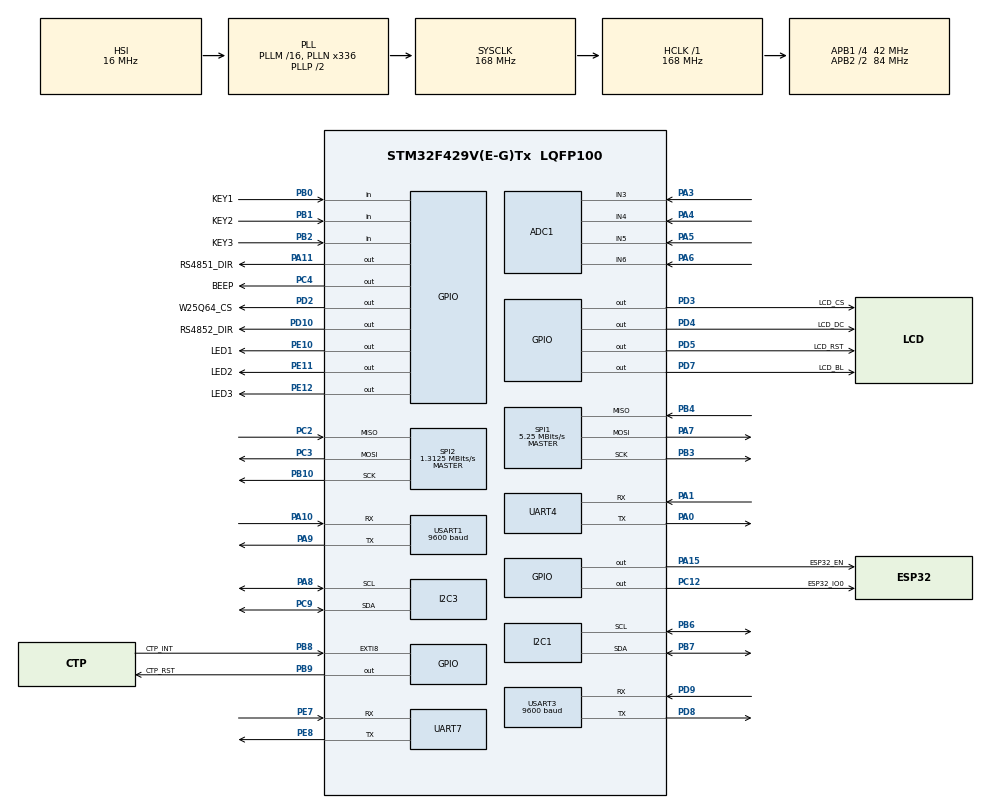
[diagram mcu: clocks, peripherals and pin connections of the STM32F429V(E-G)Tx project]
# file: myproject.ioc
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ADC1.Channel-1\#ChannelRegularConversion=ADC_CHANNEL_3
ADC1.Channel-2\#ChannelInjectedConversion=ADC_CHANNEL_3
ADC1.Channel-3\#ChannelInjectedConversion=ADC_CHANNEL_4
ADC1.Channel-4\#ChannelInjectedConversion=ADC_CHANNEL_5
ADC1.Channel-5\#ChannelInjectedConversion=ADC_CHANNEL_6
ADC1.ContinuousConvMode=ENABLE
ADC1.DMAContinuousRequests=ENABLE
ADC1.InjNumberOfConversion=4
ADC1.InjectedOffset-2\#ChannelInjectedConversion=0
ADC1.InjectedOffset-3\#ChannelInjectedConversion=0
ADC1.InjectedOffset-4\#ChannelInjectedConversion=0
ADC1.InjectedOffset-5\#ChannelInjectedConversion=0
ADC1.InjectedRank-2\#ChannelInjectedConversion=1
ADC1.InjectedRank-3\#ChannelInjectedConversion=2
ADC1.InjectedRank-4\#ChannelInjectedConversion=3
ADC1.InjectedRank-5\#ChannelInjectedConversion=4
ADC1.NbrOfConversionFlag=1
ADC1.Rank-1\#ChannelRegularConversion=1
ADC1.SamplingTime-1\#ChannelRegularConversion=ADC_SAMPLETIME_3CYCLES
ADC1.SamplingTime-2\#ChannelInjectedConversion=ADC_SAMPLETIME_144CYCLES
ADC1.SamplingTime-3\#ChannelInjectedConversion=ADC_SAMPLETIME_144CYCLES
ADC1.SamplingTime-4\#ChannelInjectedConversion=ADC_SAMPLETIME_144CYCLES
ADC1.SamplingTime-5\#ChannelInjectedConversion=ADC_SAMPLETIME_144CYCLES
ADC1.ScanConvMode=ENABLE
ADC1.master=1
Dma.ADC1.0.Direction=DMA_PERIPH_TO_MEMORY
Dma.ADC1.0.FIFOMode=DMA_FIFOMODE_DISABLE
Dma.ADC1.0.Instance=DMA2_Stream0
Dma.ADC1.0.MemDataAlignment=DMA_MDATAALIGN_HALFWORD
Dma.ADC1.0.MemInc=DMA_MINC_ENABLE
Dma.ADC1.0.Mode=DMA_CIRCULAR
Dma.ADC1.0.PeriphDataAlignment=DMA_PDATAALIGN_HALFWORD
Dma.ADC1.0.PeriphInc=DMA_PINC_DISABLE
Dma.ADC1.0.Priority=DMA_PRIORITY_LOW
Dma.Request0=ADC1
Dma.Request1=UART7_RX
Dma.Request2=SPI1_TX
Dma.Request3=USART3_RX
Dma.SPI1_TX.2.Direction=DMA_MEMORY_TO_PERIPH
Dma.SPI1_TX.2.FIFOMode=DMA_FIFOMODE_DISABLE
Dma.SPI1_TX.2.Instance=DMA2_Stream3
Dma.SPI1_TX.2.MemDataAlignment=DMA_MDATAALIGN_BYTE
Dma.SPI1_TX.2.MemInc=DMA_MINC_ENABLE
Dma.SPI1_TX.2.Mode=DMA_CIRCULAR
Dma.SPI1_TX.2.PeriphDataAlignment=DMA_PDATAALIGN_BYTE
Dma.SPI1_TX.2.PeriphInc=DMA_PINC_DISABLE
Dma.SPI1_TX.2.Priority=DMA_PRIORITY_LOW
Dma.UART7_RX.1.Direction=DMA_PERIPH_TO_MEMORY
Dma.UART7_RX.1.FIFOMode=DMA_FIFOMODE_DISABLE
Dma.UART7_RX.1.Instance=DMA1_Stream3
Dma.UART7_RX.1.MemDataAlignment=DMA_MDATAALIGN_BYTE
Dma.UART7_RX.1.MemInc=DMA_MINC_ENABLE
Dma.UART7_RX.1.Mode=DMA_CIRCULAR
Dma.UART7_RX.1.PeriphDataAlignment=DMA_PDATAALIGN_BYTE
Dma.UART7_RX.1.PeriphInc=DMA_PINC_DISABLE
Dma.UART7_RX.1.Priority=DMA_PRIORITY_LOW
Dma.USART3_RX.3.Direction=DMA_PERIPH_TO_MEMORY
Dma.USART3_RX.3.FIFOMode=DMA_FIFOMODE_DISABLE
Dma.USART3_RX.3.Instance=DMA1_Stream1
Dma.USART3_RX.3.MemDataAlignment=DMA_MDATAALIGN_BYTE
Dma.USART3_RX.3.MemInc=DMA_MINC_ENABLE
Dma.USART3_RX.3.Mode=DMA_CIRCULAR
Dma.USART3_RX.3.PeriphDataAlignment=DMA_PDATAALIGN_BYTE
Dma.USART3_RX.3.PeriphInc=DMA_PINC_DISABLE
Dma.USART3_RX.3.Priority=DMA_PRIORITY_LOW
FREERTOS.Tasks01=defaultTask,24,128,StartDefaultTask,Default,NULL,Dynamic,NULL,NULL
I2C1.I2C_Mode=I2C_Fast
IWDG.Prescaler=IWDG_PRESCALER_32
Mcu.Family=STM32F4
Mcu.Name=STM32F429V(E-G)Tx
Mcu.Package=LQFP100
NVIC.ADC_IRQn=true\:5\:0\:false\:false\:true\:true\:true\:true\:true
NVIC.DMA1_Stream1_IRQn=true\:5\:0\:false\:false\:true\:true\:false\:true\:true
NVIC.DMA1_Stream3_IRQn=true\:5\:0\:false\:false\:true\:true\:false\:true\:true
NVIC.DMA2_Stream0_IRQn=true\:5\:0\:false\:false\:true\:true\:false\:true\:true
NVIC.DMA2_Stream3_IRQn=true\:5\:0\:false\:false\:true\:true\:false\:true\:true
NVIC.EXTI9_5_IRQn=true\:5\:0\:false\:false\:true\:true\:true\:true\:true
NVIC.I2C1_ER_IRQn=true\:5\:0\:false\:false\:true\:true\:true\:true\:true
NVIC.I2C1_EV_IRQn=true\:5\:0\:false\:false\:true\:true\:true\:true\:true
NVIC.I2C3_ER_IRQn=true\:5\:0\:false\:false\:true\:true\:true\:true\:true
NVIC.I2C3_EV_IRQn=true\:5\:0\:false\:false\:true\:true\:true\:true\:true
NVIC.PriorityGroup=NVIC_PRIORITYGROUP_4
NVIC.SPI1_IRQn=true\:5\:0\:false\:false\:true\:true\:true\:true\:true
NVIC.SPI2_IRQn=true\:5\:0\:false\:false\:true\:true\:true\:true\:true
NVIC.TIM6_DAC_IRQn=true\:15\:0\:false\:false\:true\:false\:false\:true\:true
NVIC.TimeBase=TIM6_DAC_IRQn
NVIC.TimeBaseIP=TIM6
NVIC.UART4_IRQn=true\:5\:0\:false\:false\:true\:true\:true\:true\:true
NVIC.UART7_IRQn=true\:5\:0\:false\:false\:true\:true\:true\:true\:true
NVIC.USART1_IRQn=true\:5\:0\:false\:false\:true\:true\:true\:true\:true
NVIC.USART3_IRQn=true\:5\:0\:false\:false\:true\:true\:true\:true\:true
PA0/WKUP.Mode=Asynchronous
PA0/WKUP.Signal=UART4_TX
PA1.Mode=Asynchronous
PA1.Signal=UART4_RX
PA10.Mode=Asynchronous
PA10.Signal=USART1_RX
PA11.GPIO_Label=RS4851_DIR
PA11.GPIO_Speed=GPIO_SPEED_FREQ_HIGH
PA11.Signal=GPIO_Output
PA13.Mode=Serial_Wire
PA13.Signal=SYS_JTMS-SWDIO
PA14.Mode=Serial_Wire
PA14.Signal=SYS_JTCK-SWCLK
PA15.GPIO_Label=ESP32_EN
PA15.GPIO_Speed=GPIO_SPEED_FREQ_MEDIUM
PA15.PinState=GPIO_PIN_SET
PA15.Signal=GPIO_Output
PA3.Signal=ADCx_IN3
PA4.Signal=ADCx_IN4
PA5.Signal=ADCx_IN5
PA6.Signal=ADCx_IN6
PA7.Mode=Full_Duplex_Master
PA7.Signal=SPI1_MOSI
PA8.Mode=I2C
PA8.Signal=I2C3_SCL
PA9.Mode=Asynchronous
PA9.Signal=USART1_TX
PB0.GPIO_Label=KEY1
PB0.GPIO_PuPd=GPIO_PULLUP
PB0.Signal=GPIO_Input
PB1.GPIO_Label=KEY2
PB1.GPIO_PuPd=GPIO_PULLUP
PB1.Signal=GPIO_Input
PB10.Mode=Full_Duplex_Master
PB10.Signal=SPI2_SCK
PB2/BOOT1.GPIO_Label=KEY3
PB2/BOOT1.GPIO_PuPd=GPIO_PULLUP
PB2/BOOT1.Signal=GPIO_Input
PB3.Mode=Full_Duplex_Master
PB3.Signal=SPI1_SCK
PB4.Mode=Full_Duplex_Master
PB4.Signal=SPI1_MISO
PB6.Mode=I2C
PB6.Signal=I2C1_SCL
PB7.Mode=I2C
PB7.Signal=I2C1_SDA
PB8.GPIO_Label=CTP_INT
PB8.GPIO_PuPd=GPIO_PULLUP
PB8.Signal=GPXTI8
PB9.GPIO_Label=CTP_RST
PB9.GPIO_Speed=GPIO_SPEED_FREQ_MEDIUM
PB9.PinState=GPIO_PIN_SET
PB9.Signal=GPIO_Output
PC12.GPIO_Label=ESP32_IO0
PC12.GPIO_Speed=GPIO_SPEED_FREQ_HIGH
PC12.PinState=GPIO_PIN_SET
PC12.Signal=GPIO_Output
PC14/OSC32_IN.Mode=LSE-External-Oscillator
PC14/OSC32_IN.Signal=RCC_OSC32_IN
PC15/OSC32_OUT.Mode=LSE-External-Oscillator
PC15/OSC32_OUT.Signal=RCC_OSC32_OUT
PC2.Mode=Full_Duplex_Master
PC2.Signal=SPI2_MISO
PC3.Mode=Full_Duplex_Master
PC3.Signal=SPI2_MOSI
PC4.GPIO_Label=BEEP
PC4.Signal=GPIO_Output
PC9.Mode=I2C
PC9.Signal=I2C3_SDA
PD10.GPIO_Label=RS4852_DIR
PD10.GPIO_Speed=GPIO_SPEED_FREQ_HIGH
PD10.Signal=GPIO_Output
PD2.GPIO_Label=W25Q64_CS
PD2.GPIO_Speed=GPIO_SPEED_FREQ_HIGH
PD2.PinState=GPIO_PIN_SET
PD2.Signal=GPIO_Output
PD3.GPIO_Label=LCD_CS
PD3.GPIO_Speed=GPIO_SPEED_FREQ_VERY_HIGH
PD3.PinState=GPIO_PIN_SET
PD3.Signal=GPIO_Output
PD4.GPIO_Label=LCD_DC
PD4.Signal=GPIO_Output
PD5.GPIO_Label=LCD_RST
PD5.GPIO_Speed=GPIO_SPEED_FREQ_HIGH
PD5.PinState=GPIO_PIN_SET
PD5.Signal=GPIO_Output
PD7.GPIO_Label=LCD_BL
PD7.PinState=GPIO_PIN_SET
PD7.Signal=GPIO_Output
PD8.Mode=Asynchronous
PD8.Signal=USART3_TX
PD9.Mode=Asynchronous
PD9.Signal=USART3_RX
PE10.GPIO_Label=LED1
PE10.Signal=GPIO_Output
PE11.GPIO_Label=LED2
PE11.Signal=GPIO_Output
PE12.GPIO_Label=LED3
PE12.Signal=GPIO_Output
PE7.Mode=Asynchronous
PE7.Signal=UART7_RX
PE8.Mode=Asynchronous
PE8.Signal=UART7_TX
PH0/OSC_IN.Mode=HSE-External-Oscillator
PH0/OSC_IN.Signal=RCC_OSC_IN
PH1/OSC_OUT.Mode=HSE-External-Oscillator
PH1/OSC_OUT.Signal=RCC_OSC_OUT
ProjectManager.HeapSize=0x4000
ProjectManager.StackSize=0x2000
ProjectManager.TargetToolchain=CMake
RCC.48MHZClocksFreq_Value=84000000
RCC.AHBFreq_Value=168000000
RCC.APB1CLKDivider=RCC_HCLK_DIV4
RCC.APB1Freq_Value=42000000
RCC.APB1TimFreq_Value=84000000
RCC.APB2CLKDivider=RCC_HCLK_DIV2
RCC.APB2Freq_Value=84000000
RCC.APB2TimFreq_Value=168000000
RCC.CortexFreq_Value=168000000
RCC.HCLKFreq_Value=168000000
RCC.HSE_VALUE=25000000
RCC.HSI_VALUE=16000000
RCC.PLLN=336
RCC.SYSCLKFreq_VALUE=168000000
RCC.SYSCLKSource=RCC_SYSCLKSOURCE_PLLCLK
RCC.VCOOutputFreq_Value=336000000
SH.ADCx_IN3.0=ADC1_IN3,IN3
SH.ADCx_IN4.0=ADC1_IN4,IN4
SH.ADCx_IN5.0=ADC1_IN5,IN5
SH.ADCx_IN6.0=ADC1_IN6,IN6
SPI1.BaudRatePrescaler=SPI_BAUDRATEPRESCALER_16
SPI1.CalculateBaudRate=5.25 MBits/s
SPI1.Direction=SPI_DIRECTION_2LINES
SPI1.Mode=SPI_MODE_MASTER
SPI1.VirtualType=VM_MASTER
SPI2.BaudRatePrescaler=SPI_BAUDRATEPRESCALER_32
SPI2.CalculateBaudRate=1.3125 MBits/s
SPI2.Direction=SPI_DIRECTION_2LINES
SPI2.Mode=SPI_MODE_MASTER
SPI2.VirtualType=VM_MASTER
UART4.VirtualMode=Asynchronous
UART7.VirtualMode=Asynchronous
USART1.BaudRate=9600
USART1.VirtualMode=VM_ASYNC
USART3.BaudRate=9600
USART3.VirtualMode=VM_ASYNC
VP_FREERTOS_VS_CMSIS_V2.Mode=CMSIS_V2
VP_IWDG_VS_IWDG.Mode=IWDG_Activate
VP_SYS_VS_tim6.Mode=TIM6
board=custom

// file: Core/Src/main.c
/* USER CODE BEGIN Header */
/**
  ******************************************************************************
  * @file           : main.c
  * @brief          : Main program body
  ******************************************************************************
  * @attention
  *
  * Copyright (c) 2026 STMicroelectronics.
  * All rights reserved.
  *
  * This software is licensed under terms that can be found in the LICENSE file
  * in the root directory of this software component.
  * If no LICENSE file comes with this software, it is provided AS-IS.
  *
  ******************************************************************************
  */
/* USER CODE END Header */
#include "main.h"
#include "cmsis_os.h"
#include "adc.h"
#include "dma.h"
#include "i2c.h"
#include "iwdg.h"
#include "spi.h"
#include "usart.h"
#include "gpio.h"

/* USER CODE BEGIN Includes */
#include "app_main.h"
/* USER CODE END Includes */

void SystemClock_Config(void);
void MX_FREERTOS_Init(void);

int main(void)
{

  /* MCU Configuration--------------------------------------------------------*/

  /* Reset of all peripherals, Initializes the Flash interface and the Systick. */
  HAL_Init();

  /* Configure the system clock */
  SystemClock_Config();

  /* Initialize all configured peripherals */
  MX_GPIO_Init();
  MX_DMA_Init();
  MX_USART1_UART_Init();
  MX_ADC1_Init();
  MX_I2C1_Init();
  MX_I2C3_Init();
  MX_SPI1_Init();
  MX_SPI2_Init();
  MX_UART4_Init();
  MX_UART7_Init();
  MX_USART3_UART_Init();
  MX_IWDG_Init();
  /* USER CODE BEGIN 2 */

  App_MainInit();
  /* USER CODE END 2 */

  /* Init scheduler */
  osKernelInitialize();

  /* Call init function for freertos objects (in cmsis_os2.c) */
  MX_FREERTOS_Init();

  /* Start scheduler */
  osKernelStart();

  /* We should never get here as control is now taken by the scheduler */

  /* Infinite loop */
  while (1)
  {

  }
}

void SystemClock_Config(void)
{
  RCC_OscInitTypeDef RCC_OscInitStruct = {0};
  RCC_ClkInitTypeDef RCC_ClkInitStruct = {0};

  /** Configure the main internal regulator output voltage
  */
  __HAL_RCC_PWR_CLK_ENABLE();
  __HAL_PWR_VOLTAGESCALING_CONFIG(PWR_REGULATOR_VOLTAGE_SCALE1);

  /** Initializes the RCC Oscillators according to the specified parameters
  * in the RCC_OscInitTypeDef structure.
  */
  RCC_OscInitStruct.OscillatorType = RCC_OSCILLATORTYPE_HSI|RCC_OSCILLATORTYPE_LSI;
  RCC_OscInitStruct.HSIState = RCC_HSI_ON;
  RCC_OscInitStruct.HSICalibrationValue = RCC_HSICALIBRATION_DEFAULT;
  RCC_OscInitStruct.LSIState = RCC_LSI_ON;
  RCC_OscInitStruct.PLL.PLLState = RCC_PLL_ON;
  RCC_OscInitStruct.PLL.PLLSource = RCC_PLLSOURCE_HSI;
  RCC_OscInitStruct.PLL.PLLM = 16;
  RCC_OscInitStruct.PLL.PLLN = 336;
  RCC_OscInitStruct.PLL.PLLP = RCC_PLLP_DIV2;
  RCC_OscInitStruct.PLL.PLLQ = 4;
  if (HAL_RCC_OscConfig(&RCC_OscInitStruct) != HAL_OK)
  {
    Error_Handler();
  }

  /** Initializes the CPU, AHB and APB buses clocks
  */
  RCC_ClkInitStruct.ClockType = RCC_CLOCKTYPE_HCLK|RCC_CLOCKTYPE_SYSCLK
                              |RCC_CLOCKTYPE_PCLK1|RCC_CLOCKTYPE_PCLK2;
  RCC_ClkInitStruct.SYSCLKSource = RCC_SYSCLKSOURCE_PLLCLK;
  RCC_ClkInitStruct.AHBCLKDivider = RCC_SYSCLK_DIV1;
  RCC_ClkInitStruct.APB1CLKDivider = RCC_HCLK_DIV4;
  RCC_ClkInitStruct.APB2CLKDivider = RCC_HCLK_DIV2;

  if (HAL_RCC_ClockConfig(&RCC_ClkInitStruct, FLASH_LATENCY_5) != HAL_OK)
  {
    Error_Handler();
  }
}

void HAL_TIM_PeriodElapsedCallback(TIM_HandleTypeDef *htim)
{
  if (htim->Instance == TIM6)
  {
    HAL_IncTick();
  }
}

void Error_Handler(void)
{
  __disable_irq();
  while (1)
  {
  }
}

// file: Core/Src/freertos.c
/* USER CODE BEGIN Header */
/**
  ******************************************************************************
  * File Name          : freertos.c
  * Description        : Code for freertos applications
  ******************************************************************************
  * @attention
  *
  * Copyright (c) 2026 STMicroelectronics.
  * All rights reserved.
  *
  * This software is licensed under terms that can be found in the LICENSE file
  * in the root directory of this software component.
  * If no LICENSE file comes with this software, it is provided AS-IS.
  *
  ******************************************************************************
  */
/* USER CODE END Header */

#include "FreeRTOS.h"
#include "task.h"
#include "main.h"
#include "cmsis_os.h"

/* USER CODE BEGIN Includes */
#include "app_main.h"
/* USER CODE END Includes */

/* Definitions for defaultTask */
osThreadId_t defaultTaskHandle;
const osThreadAttr_t defaultTask_attributes = {
  .name = "defaultTask",
  .stack_size = 128 * 4,
  .priority = (osPriority_t) osPriorityNormal,
};

void StartDefaultTask(void *argument);

void MX_FREERTOS_Init(void); /* (MISRA C 2004 rule 8.1) */

void MX_FREERTOS_Init(void) {

  /* Create the thread(s) */
  /* creation of defaultTask */
  defaultTaskHandle = osThreadNew(StartDefaultTask, NULL, &defaultTask_attributes);

  /* USER CODE BEGIN RTOS_THREADS */
  /* add threads, ... */
  App_CreateTasks();
  /* USER CODE END RTOS_THREADS */

}

void StartDefaultTask(void *argument)
{
  for(;;)
  {
    osDelay(1);
  }
}
